# MSP430FR2355 register map
Vendor: msp430gen; File version: v0.4.0-28-gb0087ce-dirty
Registers are 16-bit, read-write, reset 0x0 unless marked. A register's access mark holds for its fields unless they carry their own. Offsets are from the block's base; [hi:lo] are bit positions; lines under a group give offsets from that group; {n}, {i} and the like mark numbered series; 'fields as' and 'values as' point back to an identical list.

## TB0
Base 0x00000380
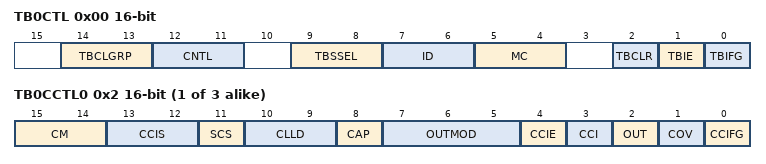
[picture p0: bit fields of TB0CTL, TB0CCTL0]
0x00 TB0CTL — Timer_B Control Register
  [14:13] TBCLGRP — TBxCLn group
    0=Each TBxCLn latch loads independently; 1=TBxCL1+TBxCL2 (TBxCCR1 CLLD bits control the update); TBxCL3+TBxCL4 (TBxCCR3 CLLD bits control the update); TBxCL5+TBxCL6 (TBxCCR5 CLLD bits control the update); TBxCL0 independent; 2=TBxCL1+TBxCL2+TBxCL3 (TBxCCR1 CLLD bits control the update); TBxCL4+TBxCL5+TBxCL6 (TBxCCR4 CLLD bits control the update); TBxCL0 independent; 3=TBxCL0+TBxCL1+TBxCL2+TBxCL3+TBxCL4+TBxCL5+TBxCL6 (TBxCCR1 CLLD bits control the update)
  [12:11] CNTL — Counter length
    0=16-bit, TBxR(max) = 0FFFFh; 1=12-bit, TBxR(max) = 0FFFh; 2=10-bit, TBxR(max) = 03FFh; 3=8-bit, TBxR(max) = 0FFh
  [9:8] TBSSEL — TimerB clock source select
    0=TBCLK (TBxCLK); 1=ACLK; 2=SMCLK; 3=INCLK
  [7:6] ID — Input divider
    0=1; 1=2; 2=4; 3=8
  [5:4] MC — Mode control
    0=STOP (Stop mode: Timer is halted); 1=UP (Up mode: Timer counts up to TBxCL0); 2=CONTINUOUS (Continuous mode: Timer counts up to the value set by CNTL); 3=UPDOWN (Up/down mode: Timer counts up to TBxCL0 then down to 0000h)
  [2] TBCLR — TimerB clear
  [1] TBIE — TimerB interrupt enable
    0=Interrupt disabled; 1=Interrupt enabled
  [0] TBIFG — TimerB interrupt flag
    0=No interrupt pending; 1=Interrupt pending
{0x2+2i} TB0CCTL{i} (i=0..2) — Timer_B Capture/Compare Control Register
  [15:14] CM — Capture mode
    0=NONE (No capture); 1=RISING (Capture on rising edge); 2=FALLING (Capture on falling edge); 3=BOTH (Capture on both rising and falling edges)
  [13:12] CCIS — Capture/compare input select
    0=CCIA (CCIxA); 1=CCIB (CCIxB); 2=GND; 3=VCC
  [11] SCS — Synchronize capture source
    0=ASYNC (Asynchronous capture); 1=SYNC (Synchronous capture)
  [10:9] CLLD — Compare latch load
    0=TBxCLn loads on write to TBxCCRn; 1=TBxCLn loads when TBxR counts to 0; 2=TBxCLn loads when TBxR counts to 0 (up or continuous mode). TBxCLn loads when TBxR counts to TBxCL0 or to 0 (up/down mode).; 3=TBxCLn loads when TBxR counts to TBxCLn
  [8] CAP — Capture mode
    0=COMPARE (Compare mode); 1=CAPTURE (Capture mode)
  [7:5] OUTMOD — Output mode
    0=OUT bit value; 1=Set; 2=Toggle/reset; 3=Set/reset; 4=Toggle; 5=Reset; 6=Toggle/set; 7=Reset/set
  [4] CCIE — Capture/compare interrupt enable
    0=Interrupt disabled; 1=Interrupt enabled
  [3] CCI ro — Capture/compare input
  [2] OUT — Output
    0=LOW (Output low); 1=HIGH (Output high)
  [1] COV — Capture overflow
    0=No capture overflow occurred; 1=Capture overflow occurred
  [0] CCIFG — Capture/compare interrupt flag
    0=No interrupt pending; 1=Interrupt pending
0x10 TB0R — Timer_B count register
{0x12+2i} TB0CCR{i} (i=0..2) — Timer_B Capture/Compare Register
0x20 TB0EX0 — Timer_Bx Expansion Register 0
  [2:0] TBIDEX — Input divider expansion
    {v}=Divide by {v+1} (v=0..7)
0x2E TB0IV — Timer_Bx Interrupt Vector Register
  [15:0] TBIV ro — Timer_B interrupt vector value
    0=NONE (No interrupt pending); 2=TBCCR1 (Interrupt Source: Capture/compare 1; Interrupt Flag: TBxCCR1 CCIFG; Interrupt Priority: Highest); 4=TBCCR2 (Interrupt Source: Capture/compare 2; Interrupt Flag: TBxCCR2 CCIFG); 6=TBCCR3 (Interrupt Source: Capture/compare 3; Interrupt Flag: TBxCCR3 CCIFG); 8=TBCCR4 (Interrupt Source: Capture/compare 4; Interrupt Flag: TBxCCR4 CCIFG); 10=TBCCR5 (Interrupt Source: Capture/compare 5; Interrupt Flag: TBxCCR5 CCIFG); 12=TBCCR6 (Interrupt Source: Capture/compare 6; Interrupt Flag: TBxCCR6 CCIFG); 14=TBIFG (Interrupt Source: Timer overflow; Interrupt Flag: TBxCTL TBIFG; Interrupt Priority: Lowest)

## TB1
Base 0x000003C0
Registers as TB0 (with TB0 read as TB1).

## TB2
Base 0x00000400
Registers as TB0 (with TB0 read as TB2).

## TB3
Base 0x00000440
Registers as TB0 (with TB0 read as TB3); these are added or differ:
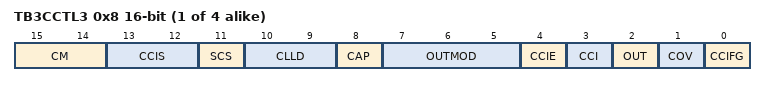
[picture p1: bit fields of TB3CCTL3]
{0x2+2i} TB3CCTL{i} (i=3..6) — Timer_B Capture/Compare Control Register
  fields as TB0.TB0CCTL0
{0x12+2i} TB3CCR{i} (i=3..6) — Timer_B Capture/Compare Register
